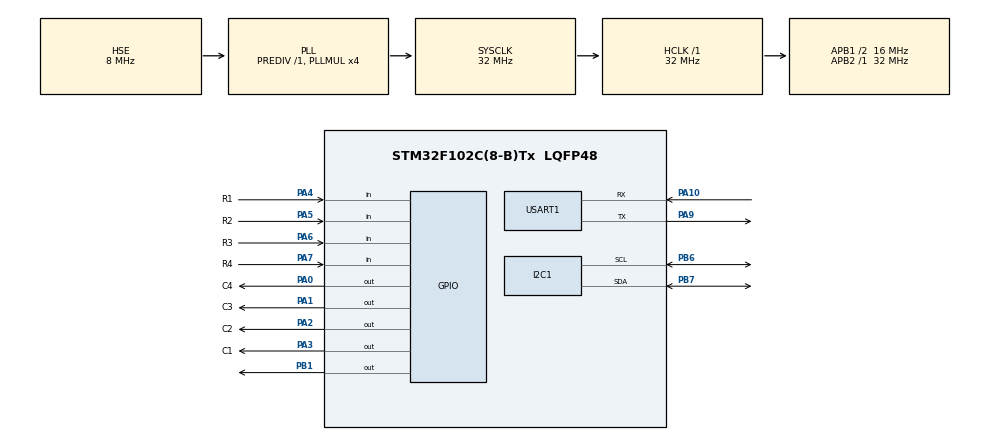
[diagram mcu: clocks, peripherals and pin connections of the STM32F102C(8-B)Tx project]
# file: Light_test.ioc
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Mcu.Family=STM32F1
Mcu.Name=STM32F102C(8-B)Tx
Mcu.Package=LQFP48
NVIC.PriorityGroup=NVIC_PRIORITYGROUP_4
PA0-WKUP.GPIO_Label=C4
PA0-WKUP.GPIO_ModeDefaultOutputPP=GPIO_MODE_OUTPUT_PP
PA0-WKUP.GPIO_PuPd=GPIO_PULLUP
PA0-WKUP.PinState=GPIO_PIN_SET
PA0-WKUP.Signal=GPIO_Output
PA1.GPIO_Label=C3
PA1.GPIO_PuPd=GPIO_PULLUP
PA1.PinState=GPIO_PIN_SET
PA1.Signal=GPIO_Output
PA10.Mode=Asynchronous
PA10.Signal=USART1_RX
PA13.Mode=Serial_Wire
PA13.Signal=SYS_JTMS-SWDIO
PA14.Mode=Serial_Wire
PA14.Signal=SYS_JTCK-SWCLK
PA2.GPIO_Label=C2
PA2.GPIO_PuPd=GPIO_PULLUP
PA2.PinState=GPIO_PIN_SET
PA2.Signal=GPIO_Output
PA3.GPIO_Label=C1
PA3.GPIO_PuPd=GPIO_PULLUP
PA3.PinState=GPIO_PIN_SET
PA3.Signal=GPIO_Output
PA4.GPIO_Label=R1
PA4.GPIO_PuPd=GPIO_PULLUP
PA4.Signal=GPIO_Input
PA5.GPIO_Label=R2
PA5.GPIO_PuPd=GPIO_PULLUP
PA5.Signal=GPIO_Input
PA6.GPIO_Label=R3
PA6.GPIO_Mode=GPIO_MODE_INPUT
PA6.GPIO_PuPd=GPIO_PULLUP
PA6.Signal=GPIO_Input
PA7.GPIO_Label=R4
PA7.GPIO_PuPd=GPIO_PULLUP
PA7.Signal=GPIO_Input
PA9.Mode=Asynchronous
PA9.Signal=USART1_TX
PB1.GPIO_Speed=GPIO_SPEED_FREQ_HIGH
PB1.Signal=GPIO_Output
PB6.Mode=I2C
PB6.Signal=I2C1_SCL
PB7.Mode=I2C
PB7.Signal=I2C1_SDA
PD0-OSC_IN.Mode=HSE-External-Oscillator
PD0-OSC_IN.Signal=RCC_OSC_IN
PD1-OSC_OUT.Mode=HSE-External-Oscillator
PD1-OSC_OUT.Signal=RCC_OSC_OUT
ProjectManager.HeapSize=0x200
ProjectManager.StackSize=0x400
ProjectManager.TargetToolchain=Makefile
RCC.AHBFreq_Value=32000000
RCC.APB1CLKDivider=RCC_HCLK_DIV2
RCC.APB1Freq_Value=16000000
RCC.APB1TimFreq_Value=32000000
RCC.APB2Freq_Value=32000000
RCC.HCLKFreq_Value=32000000
RCC.PLLMUL=RCC_PLL_MUL4
RCC.PLLSourceVirtual=RCC_PLLSOURCE_HSE
RCC.SYSCLKFreq_VALUE=32000000
RCC.SYSCLKSource=RCC_SYSCLKSOURCE_PLLCLK
RCC.USBFreq_Value=32000000
USART1.VirtualMode=VM_ASYNC
board=custom

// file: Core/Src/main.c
/* USER CODE BEGIN Header */
/**
  ******************************************************************************
  * @file           : main.c
  * @brief          : Main program body
  ******************************************************************************
  * @attention
  *
  * <h2><center>&copy; Copyright (c) 2023 STMicroelectronics.
  * All rights reserved.</center></h2>
  *
  * This software component is licensed by ST under BSD 3-Clause license,
  * the "License"; You may not use this file except in compliance with the
  * License. You may obtain a copy of the License at:
  *                        opensource.org/licenses/BSD-3-Clause
  *
  ******************************************************************************
  */
/* USER CODE END Header */
#include "main.h"
#include "i2c.h"
#include "usart.h"
#include "gpio.h"
#include "keyboard.h"
#include "OLED.h"

void SystemClock_Config(void);

int main(void)
{

  /* MCU Configuration--------------------------------------------------------*/

  /* Reset of all peripherals, Initializes the Flash interface and the Systick. */
  HAL_Init();

  /* Configure the system clock */
  SystemClock_Config();

  /* Initialize all configured peripherals */
  MX_GPIO_Init();
  MX_I2C1_Init();
  MX_USART1_UART_Init();
  OLED_Init();
  OLED_Clear();
  /* Infinite loop */
  /* USER CODE BEGIN WHILE */
  OLED_ShowString(0,0,"Hello",16);
      HAL_Delay(1000);
      OLED_Clear();
      char a[3]={0};
  while (1)
  {
    /* USER CODE END WHILE */

      KEY_Scan(a);
      if(a[0]!=0){u1_printf("(%c ,%c)\n",a[0],a[1]);a[0]=0;}

      HAL_UART_Transmit(&huart1, "6666", 4, HAL_MAX_DELAY);
  }
}

void SystemClock_Config(void)
{
  RCC_OscInitTypeDef RCC_OscInitStruct = {0};
  RCC_ClkInitTypeDef RCC_ClkInitStruct = {0};

  /** Initializes the RCC Oscillators according to the specified parameters
  * in the RCC_OscInitTypeDef structure.
  */
  RCC_OscInitStruct.OscillatorType = RCC_OSCILLATORTYPE_HSE;
  RCC_OscInitStruct.HSEState = RCC_HSE_ON;
  RCC_OscInitStruct.HSEPredivValue = RCC_HSE_PREDIV_DIV1;
  RCC_OscInitStruct.HSIState = RCC_HSI_ON;
  RCC_OscInitStruct.PLL.PLLState = RCC_PLL_ON;
  RCC_OscInitStruct.PLL.PLLSource = RCC_PLLSOURCE_HSE;
  RCC_OscInitStruct.PLL.PLLMUL = RCC_PLL_MUL4;
  if (HAL_RCC_OscConfig(&RCC_OscInitStruct) != HAL_OK)
  {
    Error_Handler();
  }
  /** Initializes the CPU, AHB and APB buses clocks
  */
  RCC_ClkInitStruct.ClockType = RCC_CLOCKTYPE_HCLK|RCC_CLOCKTYPE_SYSCLK
                              |RCC_CLOCKTYPE_PCLK1|RCC_CLOCKTYPE_PCLK2;
  RCC_ClkInitStruct.SYSCLKSource = RCC_SYSCLKSOURCE_PLLCLK;
  RCC_ClkInitStruct.AHBCLKDivider = RCC_SYSCLK_DIV1;
  RCC_ClkInitStruct.APB1CLKDivider = RCC_HCLK_DIV2;
  RCC_ClkInitStruct.APB2CLKDivider = RCC_HCLK_DIV1;

  if (HAL_RCC_ClockConfig(&RCC_ClkInitStruct, FLASH_LATENCY_1) != HAL_OK)
  {
    Error_Handler();
  }
}

void Error_Handler(void)
{
  __disable_irq();
  while (1)
  {
  }
}

/************************ (C) COPYRIGHT STMicroelectronics *****END OF FILE****/
